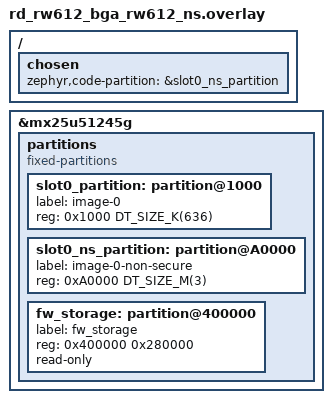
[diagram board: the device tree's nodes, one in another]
/*
 * Copyright 2025 NXP
 *
 * SPDX-License-Identifier: Apache-2.0
 */

/ {
	chosen {
		zephyr,code-partition = &slot0_ns_partition;
	};
};

&mx25u51245g {
	/delete-node/ partitions;
		partitions {
			compatible = "fixed-partitions";
			#address-cells = <1>;
			#size-cells = <1>;

			slot0_partition: partition@1000 {
				label = "image-0";
				reg = <0x1000 DT_SIZE_K(636)>;
			};

			slot0_ns_partition: partition@A0000 {
				label = "image-0-non-secure";
				reg = <0xA0000 DT_SIZE_M(3)>;  // 3 MB
			};
			
			/* This partition is reserved for connectivity firmwares storage
  			 * and shouldn't be moved.
  			 */
  			fw_storage: partition@400000 {
  				label = "fw_storage";
  				reg = <0x400000 0x280000>;
  				read-only;
  			};
	};
};
